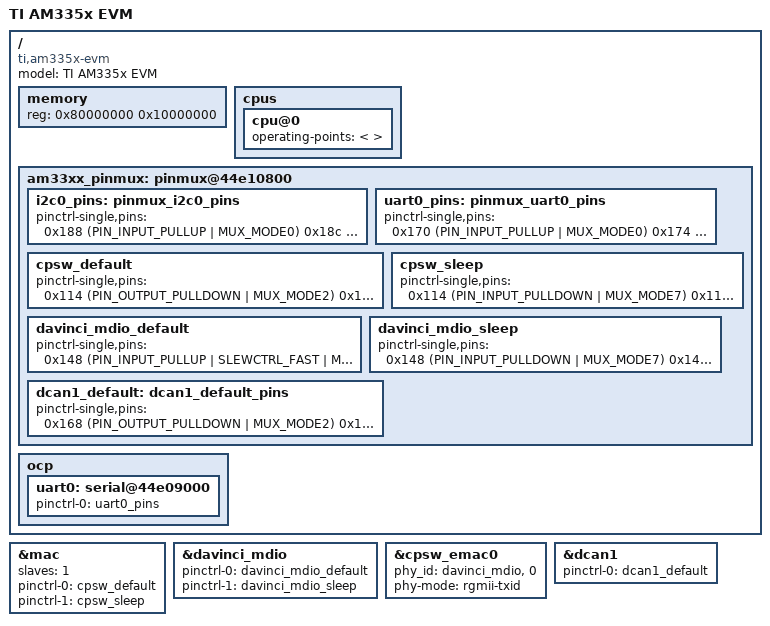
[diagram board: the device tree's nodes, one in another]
/*
 * Copyright (C) 2012 Texas Instruments Incorporated - http://www.ti.com/
 *
 * This program is free software; you can redistribute it and/or modify
 * it under the terms of the GNU General Public License version 2 as
 * published by the Free Software Foundation.
 */
/dts-v1/;

#include "am33xx.dtsi"

/ {
	model = "TI AM335x EVM";
	compatible = "ti,am335x-evm", "ti,am33xx";

	memory {
		device_type = "memory";
		reg = <0x80000000 0x10000000>; /* 256 MB */
	};

	/* You dont need operating points for cpufreq! */
	cpus {
		cpu@0 {
			operating-points = < >;
		};
	};

	am33xx_pinmux: pinmux@44e10800 {
		i2c0_pins: pinmux_i2c0_pins {
			pinctrl-single,pins = <
				0x188 (PIN_INPUT_PULLUP | MUX_MODE0)	/* i2c0_sda.i2c0_sda */
				0x18c (PIN_INPUT_PULLUP | MUX_MODE0)	/* i2c0_scl.i2c0_scl */
			>;
		};

		uart0_pins: pinmux_uart0_pins {
			pinctrl-single,pins = <
				0x170 (PIN_INPUT_PULLUP | MUX_MODE0)	/* uart0_rxd.uart0_rxd */
				0x174 (PIN_OUTPUT_PULLDOWN | MUX_MODE0)	/* uart0_txd.uart0_txd */
			>;
		};

		cpsw_default: cpsw_default {
			pinctrl-single,pins = <
				/* Slave 1 */
				0x114 (PIN_OUTPUT_PULLDOWN | MUX_MODE2)	/* mii1_txen.rgmii1_tctl */
				0x118 (PIN_INPUT_PULLDOWN | MUX_MODE2)	/* mii1_rxdv.rgmii1_rctl */
				0x11c (PIN_OUTPUT_PULLDOWN | MUX_MODE2)	/* mii1_txd3.rgmii1_td3 */
				0x120 (PIN_OUTPUT_PULLDOWN | MUX_MODE2)	/* mii1_txd2.rgmii1_td2 */
				0x124 (PIN_OUTPUT_PULLDOWN | MUX_MODE2)	/* mii1_txd1.rgmii1_td1 */
				0x128 (PIN_OUTPUT_PULLDOWN | MUX_MODE2)	/* mii1_txd0.rgmii1_td0 */
				0x12c (PIN_OUTPUT_PULLDOWN | MUX_MODE2)	/* mii1_txclk.rgmii1_tclk */
				0x130 (PIN_INPUT_PULLDOWN | MUX_MODE2)	/* mii1_rxclk.rgmii1_rclk */
				0x134 (PIN_INPUT_PULLDOWN | MUX_MODE2)	/* mii1_rxd3.rgmii1_rd3 */
				0x138 (PIN_INPUT_PULLDOWN | MUX_MODE2)	/* mii1_rxd2.rgmii1_rd2 */
				0x13c (PIN_INPUT_PULLDOWN | MUX_MODE2)	/* mii1_rxd1.rgmii1_rd1 */
				0x140 (PIN_INPUT_PULLDOWN | MUX_MODE2)	/* mii1_rxd0.rgmii1_rd0 */
			>;
		};

		cpsw_sleep: cpsw_sleep {
			pinctrl-single,pins = <
				/* Slave 1 reset value */
				0x114 (PIN_INPUT_PULLDOWN | MUX_MODE7)
				0x118 (PIN_INPUT_PULLDOWN | MUX_MODE7)
				0x11c (PIN_INPUT_PULLDOWN | MUX_MODE7)
				0x120 (PIN_INPUT_PULLDOWN | MUX_MODE7)
				0x124 (PIN_INPUT_PULLDOWN | MUX_MODE7)
				0x128 (PIN_INPUT_PULLDOWN | MUX_MODE7)
				0x12c (PIN_INPUT_PULLDOWN | MUX_MODE7)
				0x130 (PIN_INPUT_PULLDOWN | MUX_MODE7)
				0x134 (PIN_INPUT_PULLDOWN | MUX_MODE7)
				0x138 (PIN_INPUT_PULLDOWN | MUX_MODE7)
				0x13c (PIN_INPUT_PULLDOWN | MUX_MODE7)
				0x140 (PIN_INPUT_PULLDOWN | MUX_MODE7)
			>;
		};

		davinci_mdio_default: davinci_mdio_default {
			pinctrl-single,pins = <
				/* MDIO */
				0x148 (PIN_INPUT_PULLUP | SLEWCTRL_FAST | MUX_MODE0)	/* mdio_data.mdio_data */
				0x14c (PIN_OUTPUT_PULLUP | MUX_MODE0)			/* mdio_clk.mdio_clk */
			>;
		};

		davinci_mdio_sleep: davinci_mdio_sleep {
			pinctrl-single,pins = <
				/* MDIO reset value */
				0x148 (PIN_INPUT_PULLDOWN | MUX_MODE7)
				0x14c (PIN_INPUT_PULLDOWN | MUX_MODE7)
			>;
		};

		dcan1_default: dcan1_default_pins {
			pinctrl-single,pins = <
				0x168 (PIN_OUTPUT_PULLDOWN | MUX_MODE2) /* uart0_ctsn.d_can1_tx */
				0x16c (PIN_INPUT_PULLUP | MUX_MODE2) /* uart0_rtsn.d_can1_rx */
			>;
		};
	};

	ocp {
		uart0: serial@44e09000 {
			pinctrl-names = "default";
			pinctrl-0 = <&uart0_pins>;

			status = "okay";
		};
	};
};

&mac {
	slaves = <1>;
	pinctrl-names = "default", "sleep";
	pinctrl-0 = <&cpsw_default>;
	pinctrl-1 = <&cpsw_sleep>;
};

&davinci_mdio {
	pinctrl-names = "default", "sleep";
	pinctrl-0 = <&davinci_mdio_default>;
	pinctrl-1 = <&davinci_mdio_sleep>;
};

&cpsw_emac0 {
	phy_id = <&davinci_mdio>, <0>;
	phy-mode = "rgmii-txid";
};

&dcan1 {
	pinctrl-names = "default";
	pinctrl-0 = <&dcan1_default>;
	status = "okay";
};
